# STM32WBA52 register map
File version: 0.1
CPU: CM33 r0p1, little endian, MPU, FPU, 4 interrupt priority bits
Registers are 32-bit, read-write, reset 0x0 unless marked. A register's access mark holds for its fields unless they carry their own. Offsets are from the block's base; [hi:lo] are bit positions; {n}, {i} and the like mark numbered series; 'fields as' and 'values as' point back to an identical list.

## GPIOC — General-purpose I/Os
Base 0x42020800
Same registers: SEC_GPIOC 0x52020800
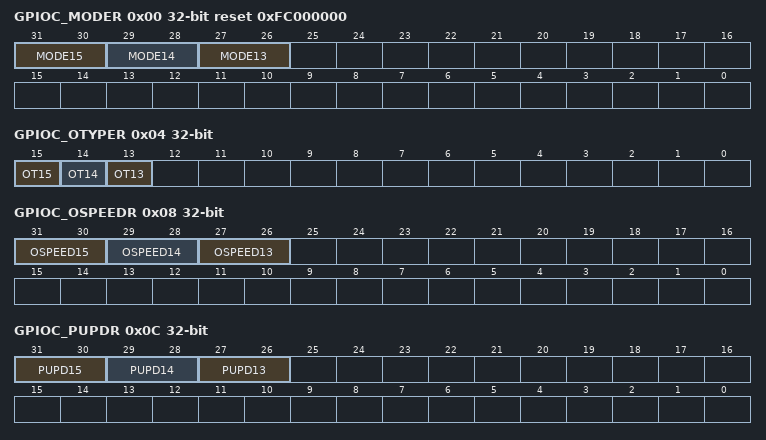
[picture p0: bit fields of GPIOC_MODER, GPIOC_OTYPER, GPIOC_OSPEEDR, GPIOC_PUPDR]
0x00 GPIOC_MODER reset 0xFC000000 — GPIO port C mode register
  [31:30] MODE15 — Port C configuration I/O pin 15 These bits are written by software to configure the I/O mode. Access can be protected by GPIOC SEC15.
    0=Input mode; 1=General purpose output mode; 2=Alternate function mode; 3=Analog mode (reset state)
  [29:28] MODE14 — Port C configuration I/O pin 14
  [27:26] MODE13 — Port C configuration I/O pin 13
0x04 GPIOC_OTYPER — GPIO port C output type register
  [all] fields
    0=Output push-pull (reset state); 1=Output open-drain
  [15] OT15 — Port C configuration I/O pin y These bits are written by software to configure the I/O output type. Access can be protected by GPIOC SECy.
  [14] OT14 — Port C configuration I/O pin y These bits are written by software to configure the I/O output type. Access can be protected by GPIOC SECy.
  [13] OT13 — Port C configuration I/O pin y These bits are written by software to configure the I/O output type. Access can be protected by GPIOC SECy.
0x08 GPIOC_OSPEEDR — GPIOC port output speed register
  [31:30] OSPEED15 — Port C configuration I/O pin 15 These bits are written by software to configure the I/O output speed. Access can be protected by GPIOC SEC15. Note: Refer to the device datasheet for the frequency specifications and the power supply and load conditions for each speed.
    0=Low speed; 1=Medium speed; 2=High speed
  [29:28] OSPEED14 — Port C configuration I/O pin 14
  [27:26] OSPEED13 — Port C configuration I/O pin 13
0x0C GPIOC_PUPDR — GPIO port C pull-up/pull-down register
  [31:30] PUPD15 — Port C configuration I/O pin 15 These bits are written by software to configure the I/O pull-up or pull-down Access can be protected by GPIOC SEC15.
    0=No pull-up, pull-down; 1=Pull-up; 2=Pull-down
  [29:28] PUPD14 — Port C configuration I/O pin 14
  [27:26] PUPD13 — Port C configuration I/O pin 13
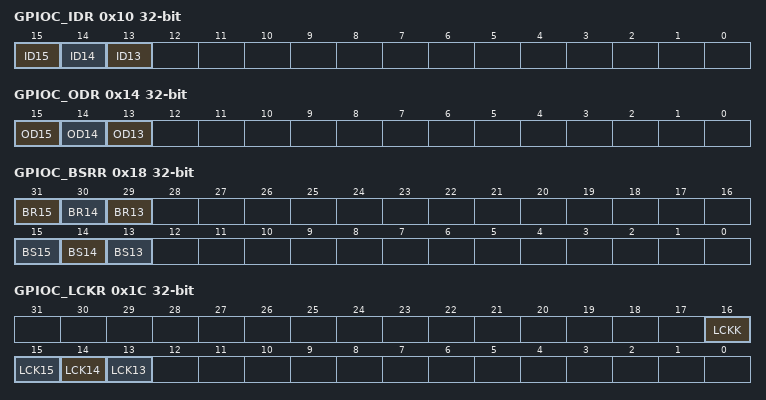
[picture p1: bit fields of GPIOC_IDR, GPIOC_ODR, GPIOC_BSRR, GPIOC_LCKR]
0x10 GPIOC_IDR ro (reset mask 0xFFFF0FFF) — GPIO port C input data register
  [15] ID15 — Port C input data I/O pin y These bits are read-only. They contain the input value of the corresponding I/O port. Access can be protected by GPIOC SECy.
  [14] ID14 — Port C input data I/O pin y These bits are read-only. They contain the input value of the corresponding I/O port. Access can be protected by GPIOC SECy.
  [13] ID13 — Port C input data I/O pin y These bits are read-only. They contain the input value of the corresponding I/O port. Access can be protected by GPIOC SECy.
0x14 GPIOC_ODR — GPIO port C output data register
  [15] OD15 — Port C output data I/O pin y These bits can be read and written by software. Access can be protected by GPIOC SECy. Note: For atomic bit set/reset, the OD bits can be individually set and/or reset by writing to the GPIOC_BSRR or GPIOC_BRR registers.
  [14] OD14 — Port C output data I/O pin y These bits can be read and written by software. Access can be protected by GPIOC SECy. Note: For atomic bit set/reset, the OD bits can be individually set and/or reset by writing to the GPIOC_BSRR or GPIOC_BRR registers.
  [13] OD13 — Port C output data I/O pin y These bits can be read and written by software. Access can be protected by GPIOC SECy. Note: For atomic bit set/reset, the OD bits can be individually set and/or reset by writing to the GPIOC_BSRR or GPIOC_BRR registers.
0x18 GPIOC_BSRR wo — GPIO port C bit set/reset register
  [31] BR15 — Port C reset I/O pin y These bits are write-only. A read to these bits returns the value 0. Access can be protected by GPIOC SECy. Note: If both BSy and BRy are set, BSy has priority.
    0=No action on the corresponding ODy bit; 1=Resets the corresponding ODy bit
  [30] BR14 — Port C reset I/O pin y These bits are write-only. A read to these bits returns the value 0. Access can be protected by GPIOC SECy. Note: If both BSy and BRy are set, BSy has priority.
    values as BR15
  [29] BR13 — Port C reset I/O pin y These bits are write-only. A read to these bits returns the value 0. Access can be protected by GPIOC SECy. Note: If both BSy and BRy are set, BSy has priority.
    values as BR15
  [15] BS15 — Port C set I/O pin y These bits are write-only. A read to these bits returns the value 0. Access can be protected by GPIOC SECy.
    0=No action on the corresponding ODy bit; 1=Sets the corresponding ODy bit
  [14] BS14 — Port C set I/O pin y These bits are write-only. A read to these bits returns the value 0. Access can be protected by GPIOC SECy.
    values as BS15
  [13] BS13 — Port C set I/O pin y These bits are write-only. A read to these bits returns the value 0. Access can be protected by GPIOC SECy.
    values as BS15
0x1C GPIOC_LCKR — GPIO port C configuration lock register
  [16] LCKK — Lock key This bit can be read any time. It can only be modified using the lock key write sequence. Access is protected by any GPIOC SECy. - LOCK key write sequence: WR LCKR[16] = 1 + LCKR[15:13] WR LCKR[16] = 0 + LCKR[15:13] WR LCKR[16] = 1 + LCKR[15:13] - LOCK key read RD LCKR[16] = 1 (this read operation is optional but it confirms that the lock is active) Note: During the LOCK key write sequence, the value of LCK[15:13] must not change. Note: Any error in the lock sequence aborts the LOCK. Note: After the first LOCK sequence on any bit of the port, any read access on the LCKK bit returns 1 until the next MCU reset or peripheral reset.
    0=Port configuration lock key not active; 1=Port configuration lock key active. The GPIOC_LCKR register is locked until the next MCU reset or peripheral reset.
  [15] LCK15 — Port C lock I/O pin y These bits are read/write but can only be written when the LCKK bit is 0 Access can be protected by GPIOC SECy.
    0=Port configuration not locked; 1=Port configuration locked
  [14] LCK14 — Port C lock I/O pin y These bits are read/write but can only be written when the LCKK bit is 0 Access can be protected by GPIOC SECy.
    0=Port configuration not locked; 1=Port configuration locked
  [13] LCK13 — Port C lock I/O pin y These bits are read/write but can only be written when the LCKK bit is 0 Access can be protected by GPIOC SECy.
    0=Port configuration not locked; 1=Port configuration locked
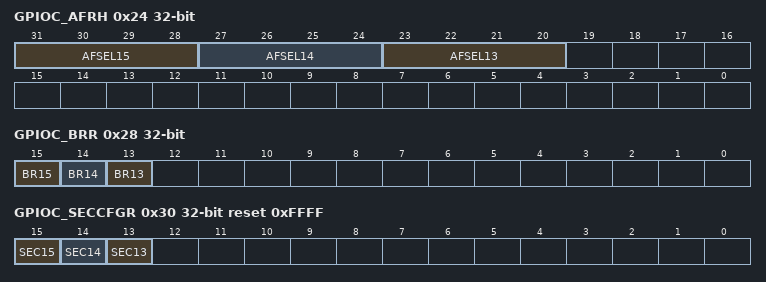
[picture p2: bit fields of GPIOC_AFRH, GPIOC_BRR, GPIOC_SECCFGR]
0x24 GPIOC_AFRH — GPIO port C alternate function high register
  [31:28] AFSEL15 — Alternate function selection for port C I/O pin 15 These bits are written by software to configure alternate function I/Os. Access can be protected by GPIOC SEC15.
    {v}=AF{v} (v=0..15)
  [27:24] AFSEL14 — Alternate function selection for port C I/O pin 14
  [23:20] AFSEL13 — Alternate function selection for port C I/O pin 13
0x28 GPIOC_BRR wo — GPIO port C bit reset register
  [all] fields
    0=No action on the corresponding ODy bit; 1=Reset the corresponding ODy bit
  [15] BR15 — Port reset I/O pin y These bits are write-only. A read to these bits returns the value 0. Access can be protected by GPIOC SECy.
  [14] BR14 — Port reset I/O pin y These bits are write-only. A read to these bits returns the value 0. Access can be protected by GPIOC SECy.
  [13] BR13 — Port reset I/O pin y These bits are write-only. A read to these bits returns the value 0. Access can be protected by GPIOC SECy.
0x30 GPIOC_SECCFGR wo reset 0xFFFF — GPIO port C secure configuration register
  [all] fields
    0=The I/O pin is non-secure; 1=The I/O pin is secure. Refer to Table 112 for all corresponding secured bits.
  [15] SEC15 — I/O pin of port C secure bit enable y These bits are written by software to enabled the security I/O port pin.
  [14] SEC14 — I/O pin of port C secure bit enable y These bits are written by software to enabled the security I/O port pin.
  [13] SEC13 — I/O pin of port C secure bit enable y These bits are written by software to enabled the security I/O port pin.
